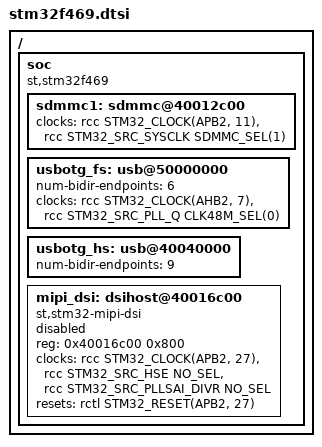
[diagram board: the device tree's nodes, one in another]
/*
 * Copyright (c) 2017 Linaro Limited
 *
 * SPDX-License-Identifier: Apache-2.0
 */

#include <st/f4/stm32f429.dtsi>
#include <zephyr/dt-bindings/mipi_dsi/mipi_dsi.h>

/ {
	soc {
		compatible = "st,stm32f469", "st,stm32f4", "simple-bus";

		sdmmc1: sdmmc@40012c00 {
			clocks = <&rcc STM32_CLOCK(APB2, 11)>,
				 <&rcc STM32_SRC_SYSCLK SDMMC_SEL(1)>;
		};

		usbotg_fs: usb@50000000 {
			num-bidir-endpoints = <6>;
			clocks = <&rcc STM32_CLOCK(AHB2, 7)>,
				 <&rcc STM32_SRC_PLL_Q CLK48M_SEL(0)>;
		};

		usbotg_hs: usb@40040000 {
			num-bidir-endpoints = <9>;
		};

		mipi_dsi: dsihost@40016c00 {
			compatible = "st,stm32-mipi-dsi";
			reg = <0x40016c00 0x800>;
			#address-cells = <1>;
			#size-cells = <0>;
			clock-names = "dsiclk", "refclk" , "pixelclk";
			clocks = <&rcc STM32_CLOCK(APB2, 27)>,
				 <&rcc STM32_SRC_HSE NO_SEL>,
				 <&rcc STM32_SRC_PLLSAI_DIVR NO_SEL>;
			resets = <&rctl STM32_RESET(APB2, 27)>;
			status = "disabled";
		};
	};
};
